# STM32N645xx register map
File version: 1.0
Registers are 32-bit, read-write, reset 0x0 unless marked. A register's access mark holds for its fields unless they carry their own. Offsets are from the block's base; [hi:lo] are bit positions; {n}, {i} and the like mark numbered series.

## FMC_Bank3_R — Flexible Memory Controller Bank3
Base 0x48024080
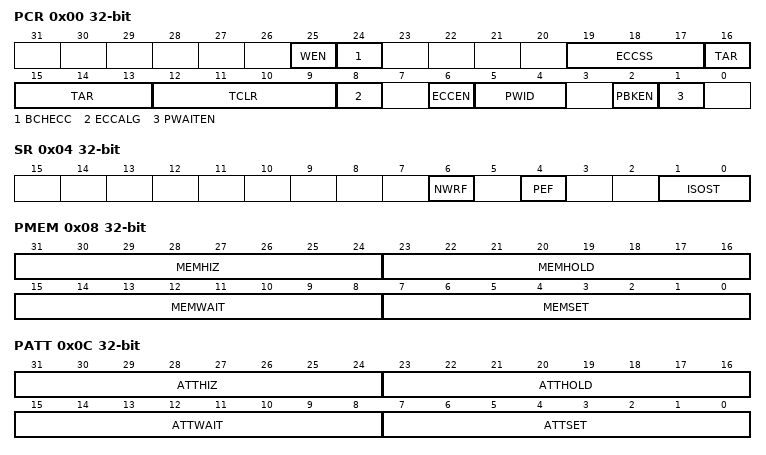
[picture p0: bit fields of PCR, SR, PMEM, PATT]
0x00 PCR — NAND Flash Programmable control register
  [25] WEN — Write enable
  [24] BCHECC — BCH error correction capability
  [19:17] ECCSS — ECC page size
  [16:13] TAR — ALE to RE delay
  [12:9] TCLR — CLE to RE delay
  [8] ECCALG — ECC algorithm
  [6] ECCEN — ECC computation logic enable bit
  [5:4] PWID — Data bus width
  [2] PBKEN — NAND Flash memory bank enable bit
  [1] PWAITEN — Wait feature enable bit
0x04 SR — FMC status register
  [6] NWRF — NAND write request flag
  [4] PEF — Pipe Empty Flag
  [1:0] ISOST — FMC isolation state with respect to the AXI interface
0x08 PMEM — Common memory space timing register
  [31:24] MEMHIZ — Common memory databus Hi-Z time
  [23:16] MEMHOLD — Common memory hold time
  [15:8] MEMWAIT — Common memory wait time
  [7:0] MEMSET — Common memory setup time
0x0C PATT — Attribute memory space timing registers
  [31:24] ATTHIZ — Attribute memory data bus Hi-Z time
  [23:16] ATTHOLD — Attribute memory hold time
  [15:8] ATTWAIT — Attribute memory wait time
  [7:0] ATTSET — Attribute memory setup time
0x10 HPR — FMC Hamming parity result registers
  [31:0] HPR — Hamming parity result
0x14 HECCR — FMC Hamming code ECC result register
  [31:0] HECC — ECC result
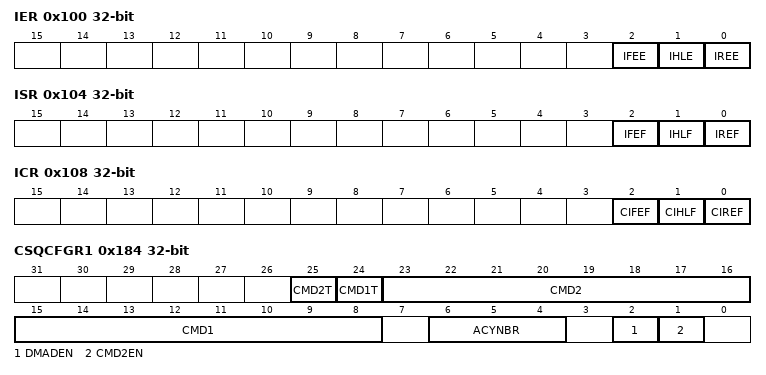
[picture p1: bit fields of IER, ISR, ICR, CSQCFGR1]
0x100 IER — FMC NAND Interrupt Enable Register
  [2] IFEE — Interrupt falling edge detection enable bit
  [1] IHLE — Interrupt high-level detection enable bit
  [0] IREE — Interrupt rising edge detection enable bit
0x104 ISR — FMC Controller Interrupt Status Register
  [2] IFEF — Interrupt falling edge flag
  [1] IHLF — Interrupt high-level flag
  [0] IREF — Interrupt rising edge flag
0x108 ICR — FMC NAND Controller Interrupt Clear Register
  [2] CIFEF — Clear Interrupt falling edge flag
  [1] CIHLF — Clear Interrupt high-level flag
  [0] CIREF — Clear Interrupt rising edge flag
0x180 CSQCR — FMC NAND Command Sequencer Control Register
  [0] CSQSTART — Command Sequencer Enable
0x184 CSQCFGR1 — FMC NAND Command Sequencer Configuration Register 1
  [25] CMD2T — Command 2 Sequencer timings
  [24] CMD1T — Command 1 Sequencer timings
  [23:16] CMD2 — Command 2 sequencer
  [15:8] CMD1 — Command 1 sequencer
  [6:4] ACYNBR — Address Cycle number
  [2] DMADEN — Command sequencer DMA request data enable
  [1] CMD2EN — Command cycle 2 Enable
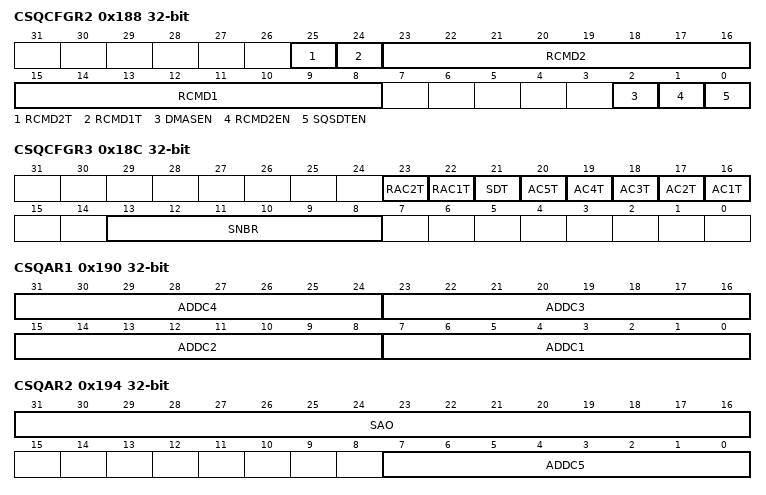
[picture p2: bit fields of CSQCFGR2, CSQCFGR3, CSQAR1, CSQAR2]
0x188 CSQCFGR2 — FMC NAND Command Sequencer Configuration Register 2
  [25] RCMD2T — Command 1 sequencer timings
  [24] RCMD1T — Command 1 sequencer timings
  [23:16] RCMD2 — Random Command 2 sequencer
  [15:8] RCMD1 — Random Command 1 sequencer
  [2] DMASEN — Command sequencer DMA request decoding status enable
  [1] RCMD2EN — Random Command 2 sequencer enable
  [0] SQSDTEN — Sequencer spare data transfer enable
0x18C CSQCFGR3 — FMC NAND sequencer configuration register 3
  [23] RAC2T — Random Address cycle 2 sequencer timings
  [22] RAC1T — Random Address cycle 1 sequencer timings
  [21] SDT — Spare data transfer sequencer timings
  [20] AC5T — Address cycle 5 sequencer timings
  [19] AC4T — Address cycle 4sequencer timings
  [18] AC3T — Address cycle 3 sequencer timings
  [17] AC2T — Address cycle 2 sequencer timings
  [16] AC1T — Address cycle 1 sequencer timings
  [13:8] SNBR — Number of sectors to be read/written
0x190 CSQAR1 — FMC NAND Command Sequencer Address Register 1
  [8n-1:8n-8] ADDC{n} (n=1..4) — Address Cycle {n}
0x194 CSQAR2 — FMC NAND Command Sequencer Address Register 2
  [31:16] SAO — Spare Area Address Offset
  [7:0] ADDC5 — Address Cycle 5
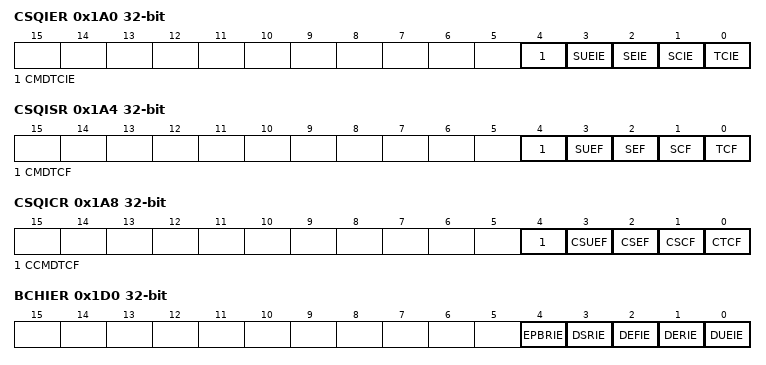
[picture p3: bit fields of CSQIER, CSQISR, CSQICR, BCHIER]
0x1A0 CSQIER — FMC NAND Command Sequencer Interrupt Enable Register
  [4] CMDTCIE — Command Transfer Complete interrupt enable
  [3] SUEIE — Sector Uncorrectable Error interrupt enable
  [2] SEIE — Sector Error interrupt enable
  [1] SCIE — Sector Complete interrupt enable
  [0] TCIE — Transfer Complete Interrupt enable
0x1A4 CSQISR — FMC NAND Command Sequencer Interrupt Status Register
  [4] CMDTCF — Command Transfer Complete flag
  [3] SUEF — Sector Uncorrectable Error flag
  [2] SEF — Sector Error flag
  [1] SCF — Sector Complete flag
  [0] TCF — Transfer Complete flag
0x1A8 CSQICR — FMC NAND Command Sequencer Interrupt Clear Register
  [4] CCMDTCF — Clear Command Transfer Complete flag
  [3] CSUEF — Clear Sector uncorrectable Error flag
  [2] CSEF — Clear Sector Error flag
  [1] CSCF — Clear Sector Complete flag
  [0] CTCF — Clear Transfer Complete flag
0x1B0 CSQEMSR — FMC Command Sequencer Error Mapping Status register
  [15:0] SEM — Sector Error mapping
0x1D0 BCHIER — FMC BCH Interrupt enable register
  [4] EPBRIE — Decoder Parity Bits Ready Interrupt enable
  [3] DSRIE — Decoder Syndrome Ready Interrupt enable
  [2] DEFIE — Decoder Error Found Interrupt enable
  [1] DERIE — Decoder Error Ready Interrupt enable
  [0] DUEIE — Decoder Uncorrectable Errors Interrupt enable
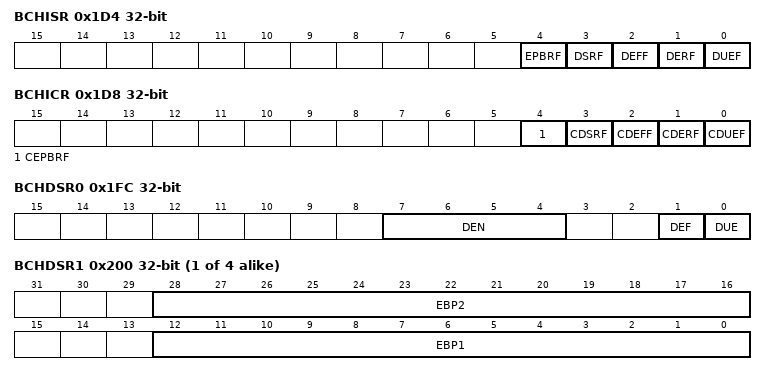
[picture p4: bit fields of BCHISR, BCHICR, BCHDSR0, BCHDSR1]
0x1D4 BCHISR — FMC BCH Interrupt and Status Register
  [4] EPBRF — Encoder Parity Bits Ready flag
  [3] DSRF — Decoder Syndrome Ready flag
  [2] DEFF — Decoder Error Found flag
  [1] DERF — Decoder Error Ready flag
  [0] DUEF — Decoder Uncorrectable Errors flag
0x1D8 BCHICR — FMC BCH Interrupt Clear Register
  [4] CEPBRF — Clear Encoder Parity Bits Ready flag
  [3] CDSRF — Clear Decoder Syndrome Ready flag
  [2] CDEFF — Clear Decoder Error Found flag
  [1] CDERF — Clear Decoder Error ready flag
  [0] CDUEF — Clear Decoder Uncorrectable Error flag
{0x1DC+4i} BCHPBR{i} (i=1..3) — FMC BCH Parity Bits Register {i}
  [31:0] BCHPB — BCH parity bits
0x1EC BCHPBR4 — FMC BCH Parity Bits Register 4
  [7:0] BCHPB — BCH parity bits
0x1FC BCHDSR0 — FMC BCH Decoder Status register 0
  [7:4] DEN — Decoder error number
  [1] DEF — Decoder error found
  [0] DUE — Decoder uncorrectable error
{0x1FC+4i} BCHDSR{i} (i=1..4) — FMC BCH Decoder Status register for bank {i}
  [28:16] EBP{2i} — Error bit position for error number {2i}
  [12:0] EBP{2i-1} — Error bit position for error number {2i-1}
